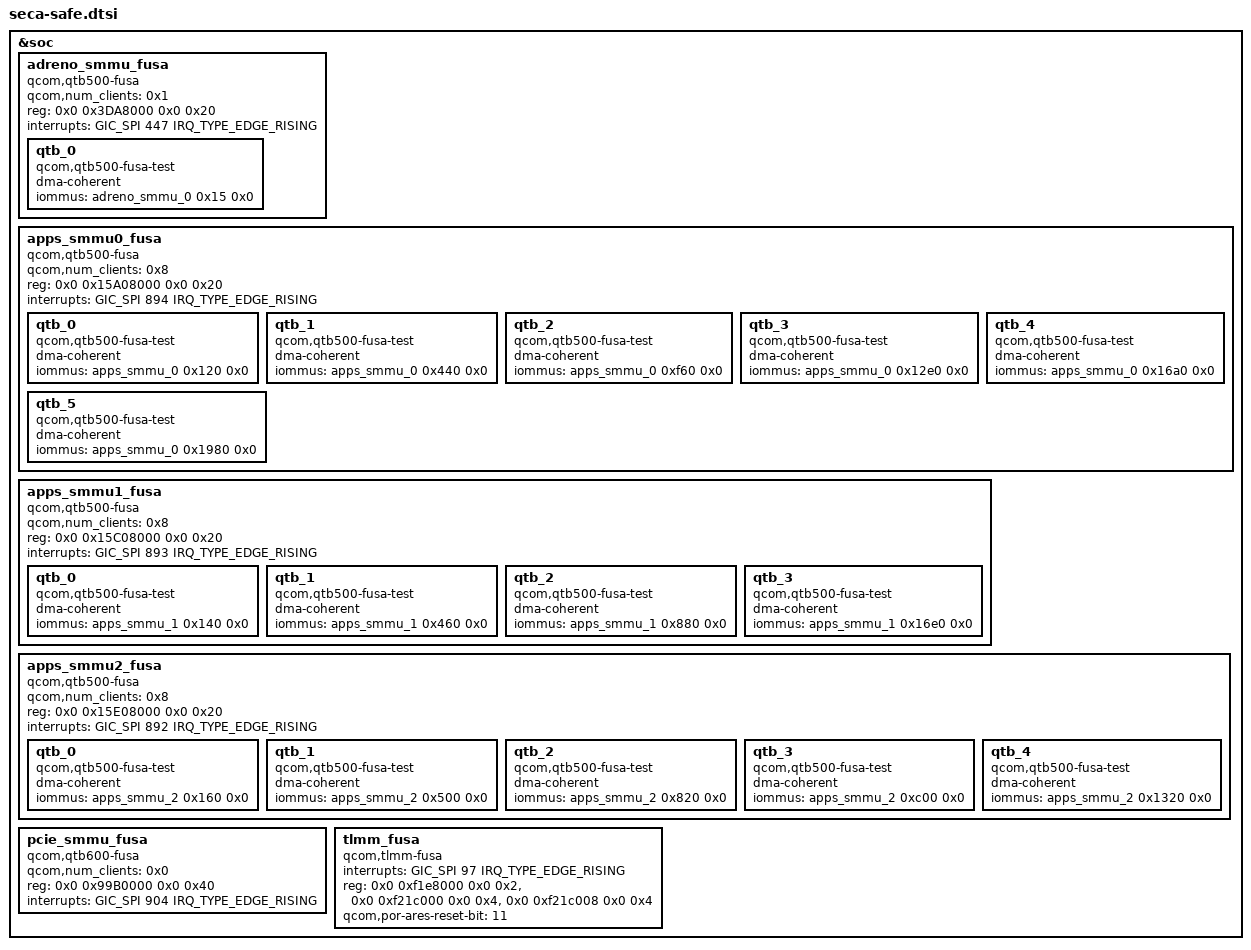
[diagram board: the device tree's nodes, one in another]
// SPDX-License-Identifier: BSD-3-Clause
/*
 * Copyright (c) Qualcomm Technologies, Inc. and/or its subsidiaries.
 */

&soc {
	adreno_smmu_fusa {
		compatible = "qcom,qtb500-fusa";
		qcom,num_clients = <0x1>;
		reg = <0x0 0x3DA8000 0x0 0x20>;
		interrupts = <GIC_SPI 447 IRQ_TYPE_EDGE_RISING>;

		qtb_0 {
			compatible = "qcom,qtb500-fusa-test";
			dma-coherent;
			iommus = <&adreno_smmu_0 0x15 0x0>;
		};
	};

	apps_smmu0_fusa {
		compatible = "qcom,qtb500-fusa";
		qcom,num_clients = <0x8>;
		reg = <0x0 0x15A08000 0x0 0x20>;
		interrupts = <GIC_SPI 894 IRQ_TYPE_EDGE_RISING>;

		qtb_0 {
			compatible = "qcom,qtb500-fusa-test";
			dma-coherent;
			iommus = <&apps_smmu_0 0x120 0x0>;
		};

		qtb_1 {
			compatible = "qcom,qtb500-fusa-test";
			dma-coherent;
			iommus = <&apps_smmu_0 0x440 0x0>;
		};

		qtb_2 {
			compatible = "qcom,qtb500-fusa-test";
			dma-coherent;
			iommus = <&apps_smmu_0 0xf60 0x0>;
		};

		qtb_3 {
			compatible = "qcom,qtb500-fusa-test";
			dma-coherent;
			iommus = <&apps_smmu_0 0x12e0 0x0>;
		};

		qtb_4 {
			compatible = "qcom,qtb500-fusa-test";
			dma-coherent;
			iommus = <&apps_smmu_0 0x16a0 0x0>;
		};

		qtb_5 {
			compatible = "qcom,qtb500-fusa-test";
			dma-coherent;
			iommus = <&apps_smmu_0 0x1980 0x0>;
		};
	};

	apps_smmu1_fusa {
		compatible = "qcom,qtb500-fusa";
		qcom,num_clients = <0x8>;
		reg = <0x0 0x15C08000 0x0 0x20>;
		interrupts = <GIC_SPI 893 IRQ_TYPE_EDGE_RISING>;

		qtb_0 {
			compatible = "qcom,qtb500-fusa-test";
			dma-coherent;
			iommus = <&apps_smmu_1 0x140 0x0>;
		};

		qtb_1 {
			compatible = "qcom,qtb500-fusa-test";
			dma-coherent;
			iommus = <&apps_smmu_1 0x460 0x0>;
		};

		qtb_2 {
			compatible = "qcom,qtb500-fusa-test";
			dma-coherent;
			iommus = <&apps_smmu_1 0x880 0x0>;
		};

		qtb_3 {
			compatible = "qcom,qtb500-fusa-test";
			dma-coherent;
			iommus = <&apps_smmu_1 0x16e0 0x0>;
		};
	};

	apps_smmu2_fusa {
		compatible = "qcom,qtb500-fusa";
		qcom,num_clients = <0x8>;
		reg = <0x0 0x15E08000 0x0 0x20>;
		interrupts = <GIC_SPI 892 IRQ_TYPE_EDGE_RISING>;

		qtb_0 {
			compatible = "qcom,qtb500-fusa-test";
			dma-coherent;
			iommus = <&apps_smmu_2 0x160 0x0>;
		};

		qtb_1 {
			compatible = "qcom,qtb500-fusa-test";
			dma-coherent;
			iommus = <&apps_smmu_2 0x500 0x0>;
		};

		qtb_2 {
			compatible = "qcom,qtb500-fusa-test";
			dma-coherent;
			iommus = <&apps_smmu_2 0x820 0x0>;
		};

		qtb_3 {
			compatible = "qcom,qtb500-fusa-test";
			dma-coherent;
			iommus = <&apps_smmu_2 0xc00 0x0>;
		};

		qtb_4 {
			compatible = "qcom,qtb500-fusa-test";
			dma-coherent;
			iommus = <&apps_smmu_2 0x1320 0x0>;
		};
	};

	pcie_smmu_fusa {
		compatible = "qcom,qtb600-fusa";
		qcom,num_clients = <0x0>;
		reg = <0x0 0x99B0000 0x0 0x40>;
		interrupts = <GIC_SPI 904 IRQ_TYPE_EDGE_RISING>;
	};

	tlmm_fusa {
		compatible = "qcom,tlmm-fusa";
		interrupts = <GIC_SPI 97 IRQ_TYPE_EDGE_RISING>;
		reg = <0x0 0xf1e8000 0x0 0x2>,
		      <0x0 0xf21c000 0x0 0x4>,
		      <0x0 0xf21c008 0x0 0x4>;
		reg-names = "error_status", "ahb_hreset_status", "por_ares_status";
		qcom,por-ares-reset-bit = <11>;
	};

};
